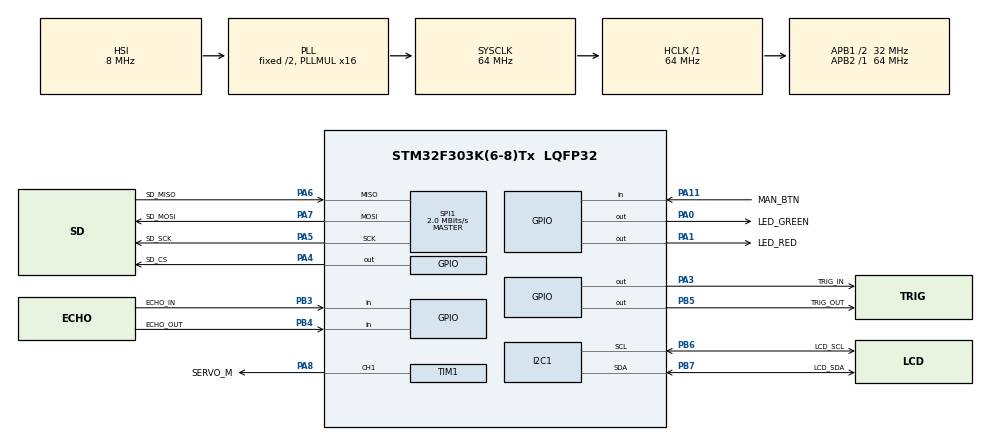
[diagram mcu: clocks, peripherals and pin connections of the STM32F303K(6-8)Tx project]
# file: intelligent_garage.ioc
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I2C1.Timing=0x00201D2B
Mcu.Family=STM32F3
Mcu.Name=STM32F303K(6-8)Tx
Mcu.Package=LQFP32
NVIC.PriorityGroup=NVIC_PRIORITYGROUP_4
PA0.GPIO_Label=LED_GREEN
PA0.Signal=GPIO_Output
PA1.GPIO_Label=LED_RED
PA1.Signal=GPIO_Output
PA11.GPIO_Label=MAN_BTN
PA11.GPIO_PuPd=GPIO_PULLUP
PA11.Signal=GPIO_Input
PA13.Mode=Serial_Wire
PA13.Signal=SYS_JTMS-SWDIO
PA14.Mode=Serial_Wire
PA14.Signal=SYS_JTCK-SWCLK
PA3.GPIO_Label=TRIG_IN
PA3.Signal=GPIO_Output
PA4.GPIO_Label=SD_CS
PA4.PinState=GPIO_PIN_SET
PA4.Signal=GPIO_Output
PA5.GPIO_Label=SD_SCK
PA5.Mode=Full_Duplex_Master
PA5.Signal=SPI1_SCK
PA6.GPIO_Label=SD_MISO
PA6.Mode=Full_Duplex_Master
PA6.Signal=SPI1_MISO
PA7.GPIO_Label=SD_MOSI
PA7.Mode=Full_Duplex_Master
PA7.Signal=SPI1_MOSI
PA8.GPIO_Label=SERVO_M
PA8.Signal=S_TIM1_CH1
PB3.GPIO_Label=ECHO_IN
PB3.Signal=GPIO_Input
PB4.GPIO_Label=ECHO_OUT
PB4.Signal=GPIO_Input
PB5.GPIO_Label=TRIG_OUT
PB5.Signal=GPIO_Output
PB6.GPIO_Label=LCD_SCL
PB6.Mode=I2C
PB6.Signal=I2C1_SCL
PB7.GPIO_Label=LCD_SDA
PB7.Mode=I2C
PB7.Signal=I2C1_SDA
ProjectManager.HeapSize=0x200
ProjectManager.StackSize=0x400
ProjectManager.TargetToolchain=STM32CubeIDE
RCC.AHBFreq_Value=64000000
RCC.APB1CLKDivider=RCC_HCLK_DIV2
RCC.APB1Freq_Value=32000000
RCC.APB1TimFreq_Value=64000000
RCC.APB2Freq_Value=64000000
RCC.APB2TimFreq_Value=64000000
RCC.CortexFreq_Value=64000000
RCC.HCLKFreq_Value=64000000
RCC.HSE_VALUE=8000000
RCC.HSI_VALUE=8000000
RCC.PLLMUL=RCC_PLL_MUL16
RCC.SYSCLKFreq_VALUE=64000000
RCC.SYSCLKSourceVirtual=RCC_SYSCLKSOURCE_PLLCLK
SH.S_TIM1_CH1.0=TIM1_CH1,PWM Generation1 CH1
SPI1.BaudRatePrescaler=SPI_BAUDRATEPRESCALER_32
SPI1.CalculateBaudRate=2.0 MBits/s
SPI1.DataSize=SPI_DATASIZE_8BIT
SPI1.Direction=SPI_DIRECTION_2LINES
SPI1.Mode=SPI_MODE_MASTER
SPI1.NSSPMode=SPI_NSS_PULSE_ENABLE
SPI1.VirtualType=VM_MASTER
TIM1.Channel-PWM\ Generation1\ CH1=TIM_CHANNEL_1
TIM1.Period=19999
TIM1.Prescaler=63
TIM1.Pulse-PWM\ Generation1\ CH1=1500
TIM2.Prescaler=63
VP_FATFS_VS_Generic.Mode=User_defined
VP_TIM2_VS_ClockSourceINT.Mode=Internal
board=custom

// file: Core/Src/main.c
/* USER CODE BEGIN Header */
/**
  ******************************************************************************
  * @file           : main.c
  * @brief          : Main program body - Intelligent Garage
  ******************************************************************************
  */
/* USER CODE END Header */
#include "main.h"
#include "fatfs.h"
#include "i2c.h"
#include "spi.h"
#include "tim.h"
#include "gpio.h"

/* USER CODE BEGIN Includes */
#include "motor.h"
#include "sensors.h"
/* USER CODE END Includes */

void SystemClock_Config(void);

int main(void)
{

  /* MCU Configuration--------------------------------------------------------*/

  /* Reset of all peripherals, Initializes the Flash interface and the Systick. */
  HAL_Init();

  /* Configure the system clock */
  SystemClock_Config();

  /* Initialize all configured peripherals */
  MX_GPIO_Init();
  MX_I2C1_Init();
  MX_SPI1_Init();
  MX_TIM1_Init();
  MX_TIM2_Init();
  MX_FATFS_Init();

  /* USER CODE BEGIN 2 */
  Motor_Init();
  Sensor_Init();
  /* USER CODE END 2 */

  /* Infinite loop */
  /* USER CODE BEGIN WHILE */
  uint32_t timer_close_start = 0;
  uint8_t timer_running = 0;

  uint8_t auto_arrived = 0;

    while (1)
    {
        Sensor_Update();
        CarPosition pos = Sensor_GetCarPosition();

        GarageCommand cmd = CMD_IDLE; // zaciatocny stav

        switch (pos) {
        	// stav auto je von a vnutri nie je
            case CAR_OUTSIDE:
                cmd = CMD_OPEN;
                timer_running = 0; // reset casovaca

                auto_arrived = 1;
                break;

            // stav auto nie je nikde
            case CAR_NONE:

             // stav auto je vnutri
            case CAR_INSIDE:
            	if (auto_arrived == 1) {

            		if (timer_running == 0) {
					  timer_close_start = HAL_GetTick();
					  timer_running = 1;
					  cmd = CMD_IDLE;
				  }
				  else {
					  if ((HAL_GetTick() - timer_close_start) > 5000) {
						  cmd = CMD_CLOSE;
						  // reset flagov
						  auto_arrived = 0;
						  timer_running = 0;
					  } else {
						  cmd = CMD_IDLE;
					  }
				  }
			  }
			  else {
				  // nebol stav CAR_OUTSIDE teda auto bolo uz vnutri
				  cmd = CMD_IDLE;
				  timer_running = 0;
			  }
			  break;

            case CAR_BOTH:

                if (timer_running == 0) {
                    // Ak casovac este nebezi, spusti ho teraz
                    timer_close_start = HAL_GetTick();
                    timer_running = 1;
                    cmd = CMD_IDLE; // Zatial cakame
                }
                else {
                    // Casovac bezi, skontroluj ci preslo 5000 ms (5 sekund)
                    if ((HAL_GetTick() - timer_close_start) > 5000) {
                        cmd = CMD_CLOSE; // Preslo 5 sekund -> ZATVOR
                    } else {
                        cmd = CMD_IDLE;  // Este nepreslo 5 sekund -> CAKAJ
                    }
                }
                break;
        }

        // 3. Posli prikaz motoru
        Motor_Process(cmd);

        HAL_Delay(50);
    }
}

void SystemClock_Config(void)
{
  RCC_OscInitTypeDef RCC_OscInitStruct = {0};
  RCC_ClkInitTypeDef RCC_ClkInitStruct = {0};
  RCC_PeriphCLKInitTypeDef PeriphClkInit = {0};

  /** Initializes the RCC Oscillators according to the specified parameters
  * in the RCC_OscInitTypeDef structure.
  */
  RCC_OscInitStruct.OscillatorType = RCC_OSCILLATORTYPE_HSI;
  RCC_OscInitStruct.HSIState = RCC_HSI_ON;
  RCC_OscInitStruct.HSICalibrationValue = RCC_HSICALIBRATION_DEFAULT;
  RCC_OscInitStruct.PLL.PLLState = RCC_PLL_ON;
  RCC_OscInitStruct.PLL.PLLSource = RCC_PLLSOURCE_HSI;
  RCC_OscInitStruct.PLL.PLLMUL = RCC_PLL_MUL16;
  if (HAL_RCC_OscConfig(&RCC_OscInitStruct) != HAL_OK)
  {
    Error_Handler();
  }

  /** Initializes the CPU, AHB and APB buses clocks
  */
  RCC_ClkInitStruct.ClockType = RCC_CLOCKTYPE_HCLK|RCC_CLOCKTYPE_SYSCLK
                              |RCC_CLOCKTYPE_PCLK1|RCC_CLOCKTYPE_PCLK2;
  RCC_ClkInitStruct.SYSCLKSource = RCC_SYSCLKSOURCE_PLLCLK;
  RCC_ClkInitStruct.AHBCLKDivider = RCC_SYSCLK_DIV1;
  RCC_ClkInitStruct.APB1CLKDivider = RCC_HCLK_DIV2;
  RCC_ClkInitStruct.APB2CLKDivider = RCC_HCLK_DIV1;

  if (HAL_RCC_ClockConfig(&RCC_ClkInitStruct, FLASH_LATENCY_2) != HAL_OK)
  {
    Error_Handler();
  }
  PeriphClkInit.PeriphClockSelection = RCC_PERIPHCLK_I2C1|RCC_PERIPHCLK_TIM1;
  PeriphClkInit.I2c1ClockSelection = RCC_I2C1CLKSOURCE_HSI;
  PeriphClkInit.Tim1ClockSelection = RCC_TIM1CLK_HCLK;
  if (HAL_RCCEx_PeriphCLKConfig(&PeriphClkInit) != HAL_OK)
  {
    Error_Handler();
  }
}

void Error_Handler(void)
{
  __disable_irq();
  while (1)
  {
  }
}
